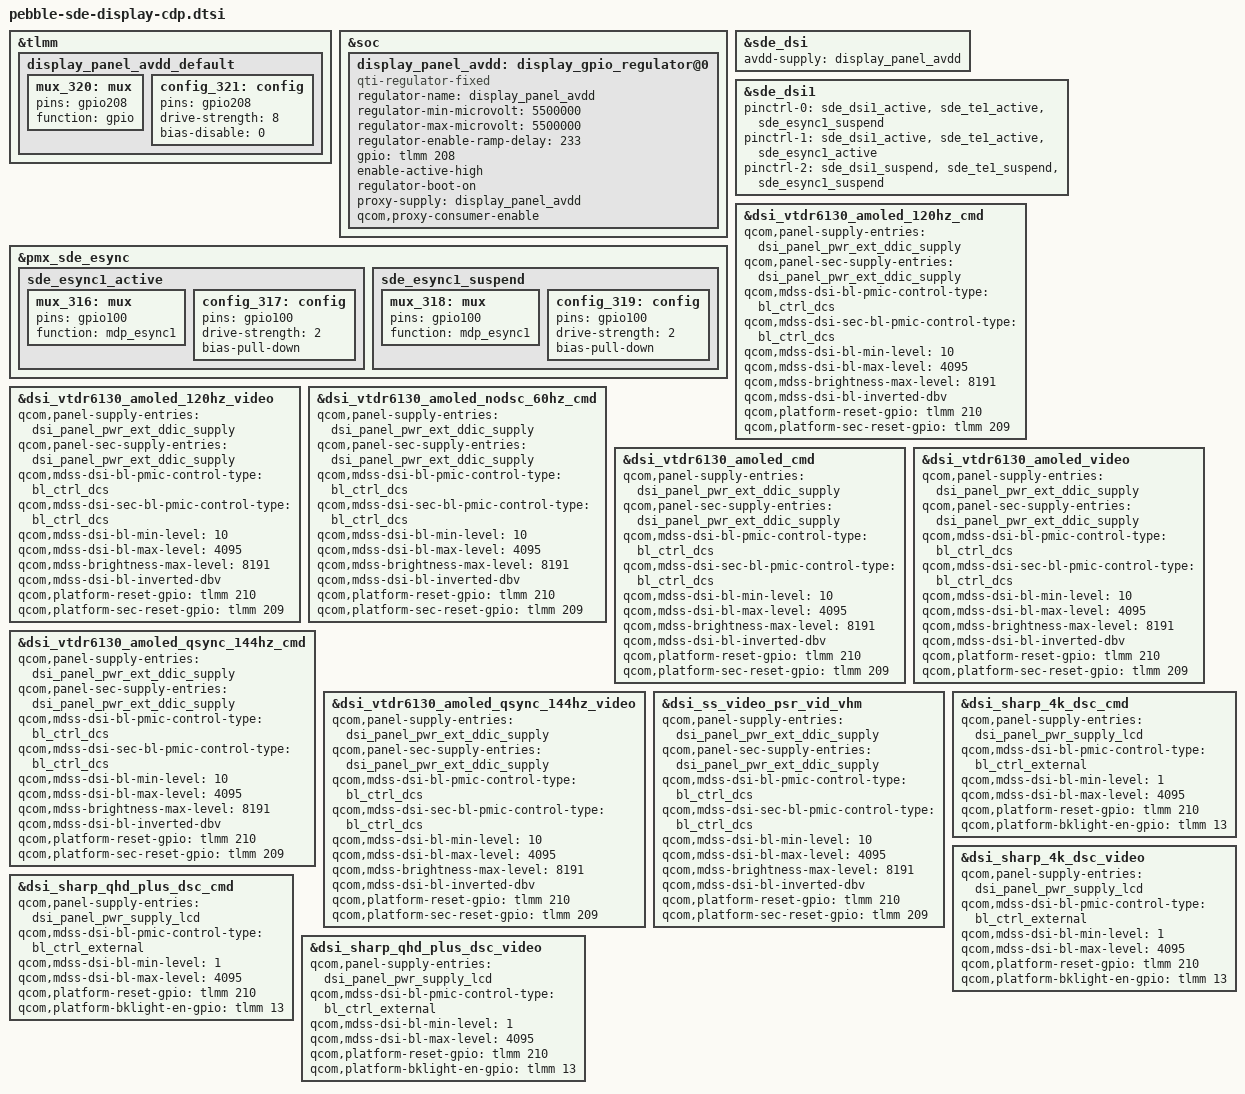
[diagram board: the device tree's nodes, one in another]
// SPDX-License-Identifier: BSD-3-Clause
/*
 * Copyright (c) Qualcomm Technologies, Inc. and/or its subsidiaries.
 */

#include "pebble-sde-display-mtp.dtsi"

&tlmm {
	display_panel_avdd_default: display_panel_avdd_default {
		mux_320: mux {
			pins = "gpio208";
			function = "gpio";
		};

		config_321: config {
			pins = "gpio208";
			drive-strength = <8>;   /* 8 mA */
			bias-disable = <0>;   /* no pull */
		};
	};
};

&soc {
	display_panel_avdd: display_gpio_regulator@0 {
		compatible = "qti-regulator-fixed";
		regulator-name = "display_panel_avdd";
		regulator-min-microvolt = <5500000>;
		regulator-max-microvolt = <5500000>;
		regulator-enable-ramp-delay = <233>;
		gpio = <&tlmm 208 0>;
		enable-active-high;
		regulator-boot-on;
		proxy-supply = <&display_panel_avdd>;
		qcom,proxy-consumer-enable;
		pinctrl-names = "default";
	};
};

&pmx_sde_esync {
	sde_esync1_active: sde_esync1_active {
		mux_316: mux {
			pins = "gpio100";
			function = "mdp_esync1";
		};

		config_317: config {
			pins = "gpio100";
			drive-strength = <2>;   /* 2 mA */
			bias-pull-down;         /* PULL DOWN */
		};
	};

	sde_esync1_suspend: sde_esync1_suspend {
		mux_318: mux {
			pins = "gpio100";
			function = "mdp_esync1";
		};

		config_319: config {
			pins = "gpio100";
			drive-strength = <2>;   /* 2 mA */
			bias-pull-down;         /* PULL DOWN */
		};
	};
};

&sde_dsi {
	avdd-supply = <&display_panel_avdd>;
};

&sde_dsi1 {
	pinctrl-names = "panel_active", "panel_active_with_esync", "panel_suspend";
	pinctrl-0 = <&sde_dsi1_active &sde_te1_active &sde_esync1_suspend>;
	pinctrl-1 = <&sde_dsi1_active &sde_te1_active &sde_esync1_active>;
	pinctrl-2 = <&sde_dsi1_suspend &sde_te1_suspend &sde_esync1_suspend>;
};

&dsi_vtdr6130_amoled_120hz_cmd {
	qcom,panel-supply-entries = <&dsi_panel_pwr_ext_ddic_supply>;
	qcom,panel-sec-supply-entries = <&dsi_panel_pwr_ext_ddic_supply>;
	qcom,mdss-dsi-bl-pmic-control-type = "bl_ctrl_dcs";
	qcom,mdss-dsi-sec-bl-pmic-control-type = "bl_ctrl_dcs";
	qcom,mdss-dsi-bl-min-level = <10>;
	qcom,mdss-dsi-bl-max-level = <4095>;
	qcom,mdss-brightness-max-level = <8191>;
	qcom,mdss-dsi-bl-inverted-dbv;
	qcom,platform-reset-gpio = <&tlmm 210 0>;
	qcom,platform-sec-reset-gpio = <&tlmm 209 0>;
};

&dsi_vtdr6130_amoled_120hz_video {
	qcom,panel-supply-entries = <&dsi_panel_pwr_ext_ddic_supply>;
	qcom,panel-sec-supply-entries = <&dsi_panel_pwr_ext_ddic_supply>;
	qcom,mdss-dsi-bl-pmic-control-type = "bl_ctrl_dcs";
	qcom,mdss-dsi-sec-bl-pmic-control-type = "bl_ctrl_dcs";
	qcom,mdss-dsi-bl-min-level = <10>;
	qcom,mdss-dsi-bl-max-level = <4095>;
	qcom,mdss-brightness-max-level = <8191>;
	qcom,mdss-dsi-bl-inverted-dbv;
	qcom,platform-reset-gpio = <&tlmm 210 0>;
	qcom,platform-sec-reset-gpio = <&tlmm 209 0>;
};

&dsi_vtdr6130_amoled_nodsc_60hz_cmd {
	qcom,panel-supply-entries = <&dsi_panel_pwr_ext_ddic_supply>;
	qcom,panel-sec-supply-entries = <&dsi_panel_pwr_ext_ddic_supply>;
	qcom,mdss-dsi-bl-pmic-control-type = "bl_ctrl_dcs";
	qcom,mdss-dsi-sec-bl-pmic-control-type = "bl_ctrl_dcs";
	qcom,mdss-dsi-bl-min-level = <10>;
	qcom,mdss-dsi-bl-max-level = <4095>;
	qcom,mdss-brightness-max-level = <8191>;
	qcom,mdss-dsi-bl-inverted-dbv;
	qcom,platform-reset-gpio = <&tlmm 210 0>;
	qcom,platform-sec-reset-gpio = <&tlmm 209 0>;
};

&dsi_vtdr6130_amoled_cmd {
	qcom,panel-supply-entries = <&dsi_panel_pwr_ext_ddic_supply>;
	qcom,panel-sec-supply-entries = <&dsi_panel_pwr_ext_ddic_supply>;
	qcom,mdss-dsi-bl-pmic-control-type = "bl_ctrl_dcs";
	qcom,mdss-dsi-sec-bl-pmic-control-type = "bl_ctrl_dcs";
	qcom,mdss-dsi-bl-min-level = <10>;
	qcom,mdss-dsi-bl-max-level = <4095>;
	qcom,mdss-brightness-max-level = <8191>;
	qcom,mdss-dsi-bl-inverted-dbv;
	qcom,platform-reset-gpio = <&tlmm 210 0>;
	qcom,platform-sec-reset-gpio = <&tlmm 209 0>;
};

&dsi_vtdr6130_amoled_video {
	qcom,panel-supply-entries = <&dsi_panel_pwr_ext_ddic_supply>;
	qcom,panel-sec-supply-entries = <&dsi_panel_pwr_ext_ddic_supply>;
	qcom,mdss-dsi-bl-pmic-control-type = "bl_ctrl_dcs";
	qcom,mdss-dsi-sec-bl-pmic-control-type = "bl_ctrl_dcs";
	qcom,mdss-dsi-bl-min-level = <10>;
	qcom,mdss-dsi-bl-max-level = <4095>;
	qcom,mdss-brightness-max-level = <8191>;
	qcom,mdss-dsi-bl-inverted-dbv;
	qcom,platform-reset-gpio = <&tlmm 210 0>;
	qcom,platform-sec-reset-gpio = <&tlmm 209 0>;
};

&dsi_vtdr6130_amoled_qsync_144hz_cmd {
	qcom,panel-supply-entries = <&dsi_panel_pwr_ext_ddic_supply>;
	qcom,panel-sec-supply-entries = <&dsi_panel_pwr_ext_ddic_supply>;
	qcom,mdss-dsi-bl-pmic-control-type = "bl_ctrl_dcs";
	qcom,mdss-dsi-sec-bl-pmic-control-type = "bl_ctrl_dcs";
	qcom,mdss-dsi-bl-min-level = <10>;
	qcom,mdss-dsi-bl-max-level = <4095>;
	qcom,mdss-brightness-max-level = <8191>;
	qcom,mdss-dsi-bl-inverted-dbv;
	qcom,platform-reset-gpio = <&tlmm 210 0>;
	qcom,platform-sec-reset-gpio = <&tlmm 209 0>;
};

&dsi_vtdr6130_amoled_qsync_144hz_video {
	qcom,panel-supply-entries = <&dsi_panel_pwr_ext_ddic_supply>;
	qcom,panel-sec-supply-entries = <&dsi_panel_pwr_ext_ddic_supply>;
	qcom,mdss-dsi-bl-pmic-control-type = "bl_ctrl_dcs";
	qcom,mdss-dsi-sec-bl-pmic-control-type = "bl_ctrl_dcs";
	qcom,mdss-dsi-bl-min-level = <10>;
	qcom,mdss-dsi-bl-max-level = <4095>;
	qcom,mdss-brightness-max-level = <8191>;
	qcom,mdss-dsi-bl-inverted-dbv;
	qcom,platform-reset-gpio = <&tlmm 210 0>;
	qcom,platform-sec-reset-gpio = <&tlmm 209 0>;
};

&dsi_ss_video_psr_vid_vhm {
	qcom,panel-supply-entries = <&dsi_panel_pwr_ext_ddic_supply>;
	qcom,panel-sec-supply-entries = <&dsi_panel_pwr_ext_ddic_supply>;
	qcom,mdss-dsi-bl-pmic-control-type = "bl_ctrl_dcs";
	qcom,mdss-dsi-sec-bl-pmic-control-type = "bl_ctrl_dcs";
	qcom,mdss-dsi-bl-min-level = <10>;
	qcom,mdss-dsi-bl-max-level = <4095>;
	qcom,mdss-brightness-max-level = <8191>;
	qcom,mdss-dsi-bl-inverted-dbv;
	qcom,platform-reset-gpio = <&tlmm 210 0>;
	qcom,platform-sec-reset-gpio = <&tlmm 209 0>;
};

&dsi_sharp_4k_dsc_cmd {
	qcom,panel-supply-entries = <&dsi_panel_pwr_supply_lcd>;
	qcom,mdss-dsi-bl-pmic-control-type = "bl_ctrl_external";
	qcom,mdss-dsi-bl-min-level = <1>;
	qcom,mdss-dsi-bl-max-level = <4095>;
	qcom,platform-reset-gpio = <&tlmm 210 0>;
	qcom,platform-bklight-en-gpio = <&tlmm 13 0>;
};

&dsi_sharp_4k_dsc_video {
	qcom,panel-supply-entries = <&dsi_panel_pwr_supply_lcd>;
	qcom,mdss-dsi-bl-pmic-control-type = "bl_ctrl_external";
	qcom,mdss-dsi-bl-min-level = <1>;
	qcom,mdss-dsi-bl-max-level = <4095>;
	qcom,platform-reset-gpio = <&tlmm 210 0>;
	qcom,platform-bklight-en-gpio = <&tlmm 13 0>;
};

&dsi_sharp_qhd_plus_dsc_cmd {
	qcom,panel-supply-entries = <&dsi_panel_pwr_supply_lcd>;
	qcom,mdss-dsi-bl-pmic-control-type = "bl_ctrl_external";
	qcom,mdss-dsi-bl-min-level = <1>;
	qcom,mdss-dsi-bl-max-level = <4095>;
	qcom,platform-reset-gpio = <&tlmm 210 0>;
	qcom,platform-bklight-en-gpio = <&tlmm 13 0>;
};

&dsi_sharp_qhd_plus_dsc_video {
	qcom,panel-supply-entries = <&dsi_panel_pwr_supply_lcd>;
	qcom,mdss-dsi-bl-pmic-control-type = "bl_ctrl_external";
	qcom,mdss-dsi-bl-min-level = <1>;
	qcom,mdss-dsi-bl-max-level = <4095>;
	qcom,platform-reset-gpio = <&tlmm 210 0>;
	qcom,platform-bklight-en-gpio = <&tlmm 13 0>;
};
